# M4KQ register map
File version: 0.1
Registers are 32-bit, read-write, reset 0x0 unless marked. A register's access mark holds for its fields unless they carry their own. Offsets are from the block's base; [hi:lo] are bit positions; {n}, {i} and the like mark numbered series.

## PR — Port R
Base 0x400E0E00
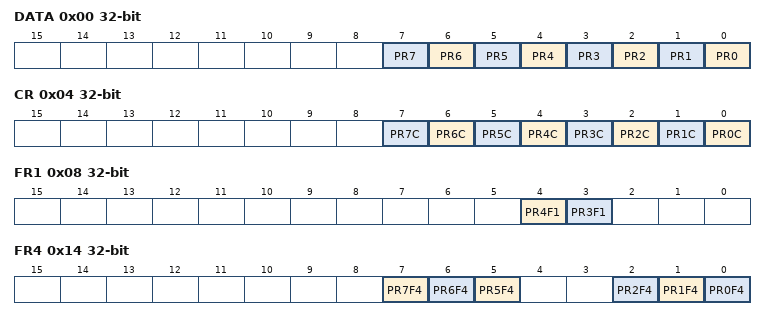
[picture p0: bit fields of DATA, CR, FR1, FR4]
0x00 DATA — Port R Data Register
  [n] PR{n} (n=0..7)
0x04 CR — Port R Output Control Register
  [n] PR{n}C (n=0..7)
0x08 FR1 — Port R Function Register 1
  [4] PR4F1, [3] PR3F1
0x14 FR4 — Port R Function Register 4
  [7] PR7F4, [6] PR6F4, [5] PR5F4, [2] PR2F4, [1] PR1F4, [0] PR0F4
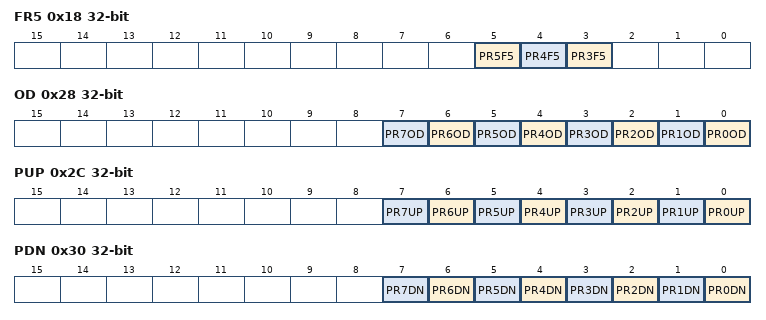
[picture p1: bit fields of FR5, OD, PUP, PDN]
0x18 FR5 — Port R Function Register 5
  [5] PR5F5, [4] PR4F5, [3] PR3F5
0x28 OD — Port R Open Drain Control Register
  [n] PR{n}OD (n=0..7)
0x2C PUP — Port R Pull-up Control Register
  [n] PR{n}UP (n=0..7)
0x30 PDN — Port R Pull-down Control Register
  [n] PR{n}DN (n=0..7)
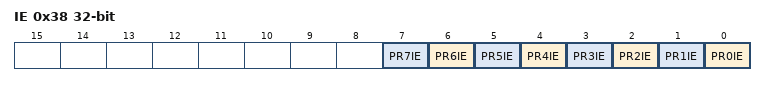
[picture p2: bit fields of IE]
0x38 IE — Port R Input Control Register
  [n] PR{n}IE (n=0..7)

## PT — Port T
Base 0x400E0F00
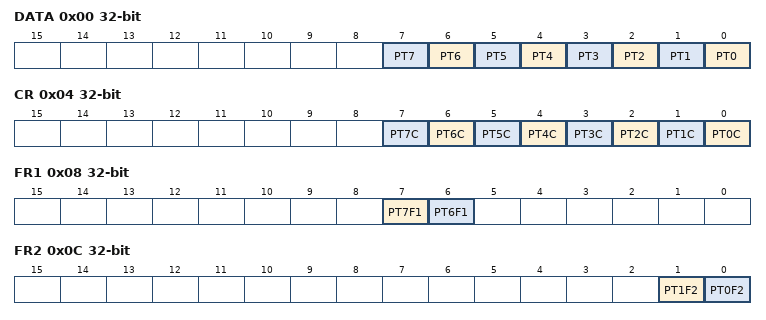
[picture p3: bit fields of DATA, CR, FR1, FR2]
0x00 DATA — Port T Data Register
  [n] PT{n} (n=0..7)
0x04 CR — Port T Output Control Register
  [n] PT{n}C (n=0..7)
0x08 FR1 — Port T Function Register 1
  [7] PT7F1, [6] PT6F1
0x0C FR2 — Port T Function Register 2
  [1] PT1F2, [0] PT0F2
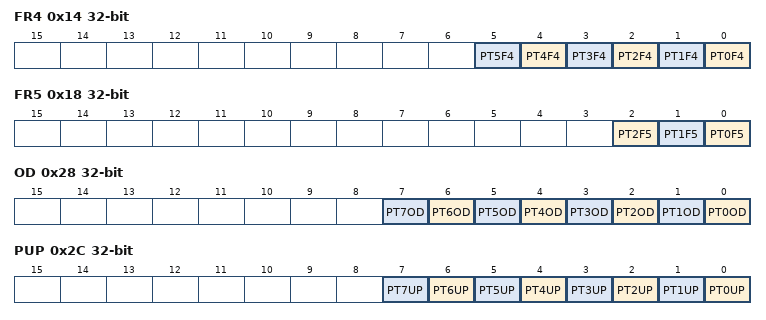
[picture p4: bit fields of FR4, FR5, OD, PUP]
0x14 FR4 — Port T Function Register 4
  [n] PT{n}F4 (n=0..5)
0x18 FR5 — Port T Function Register 5
  [2] PT2F5, [1] PT1F5, [0] PT0F5
0x28 OD — Port T Open Drain Control Register
  [n] PT{n}OD (n=0..7)
0x2C PUP — Port T Pull-up Control Register
  [n] PT{n}UP (n=0..7)
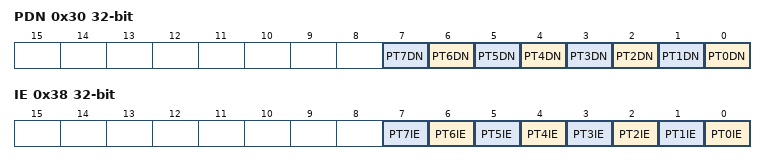
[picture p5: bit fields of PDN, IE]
0x30 PDN — Port T Pull-down Control Register
  [n] PT{n}DN (n=0..7)
0x38 IE — Port T Input Control Register
  [n] PT{n}IE (n=0..7)

## PU — Port U
Base 0x400E1000
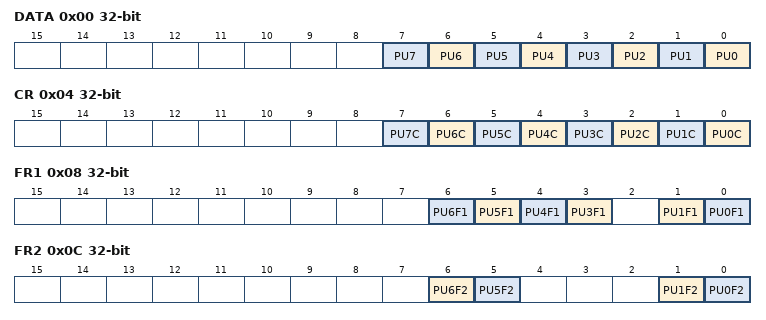
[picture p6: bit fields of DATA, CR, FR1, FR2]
0x00 DATA — Port U Data Register
  [n] PU{n} (n=0..7)
0x04 CR — Port U Output Control Register
  [n] PU{n}C (n=0..7)
0x08 FR1 — Port U Function Register 1
  [n] PU{n}F1 (n=3..6), [1] PU1F1, [0] PU0F1
0x0C FR2 — Port U Function Register 2
  [6] PU6F2, [5] PU5F2, [1] PU1F2, [0] PU0F2
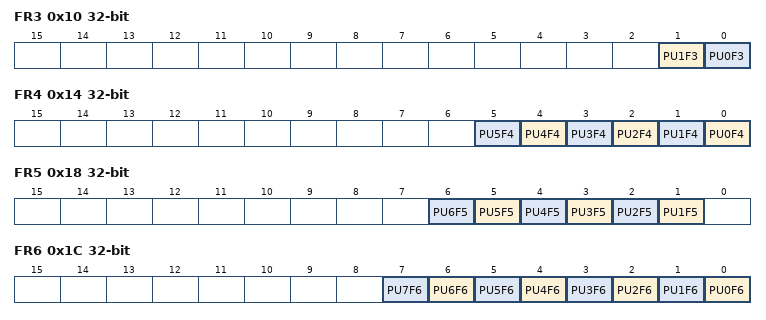
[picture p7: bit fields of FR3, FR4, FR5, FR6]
0x10 FR3 — Port U Function Register 3
  [1] PU1F3, [0] PU0F3
0x14 FR4 — Port U Function Register 4
  [n] PU{n}F4 (n=0..5)
0x18 FR5 — Port U Function Register 5
  [n] PU{n}F5 (n=1..6)
0x1C FR6 — Port U Function Register 6
  [n] PU{n}F6 (n=0..7)
0x20 FR7 — Port U Function Register 7
  [7] PU7F7
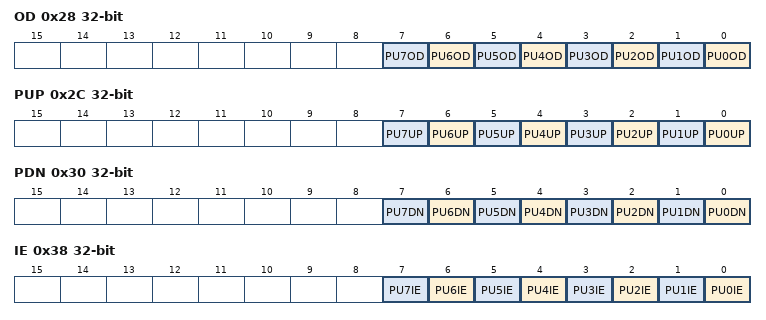
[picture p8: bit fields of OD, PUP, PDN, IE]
0x28 OD — Port U Open Drain Control Register
  [n] PU{n}OD (n=0..7)
0x2C PUP — Port U Pull-up Control Register
  [n] PU{n}UP (n=0..7)
0x30 PDN — Port U Pull-down Control Register
  [n] PU{n}DN (n=0..7)
0x38 IE — Port U Input Control Register
  [n] PU{n}IE (n=0..7)

## PV — Port V
Base 0x400E1100
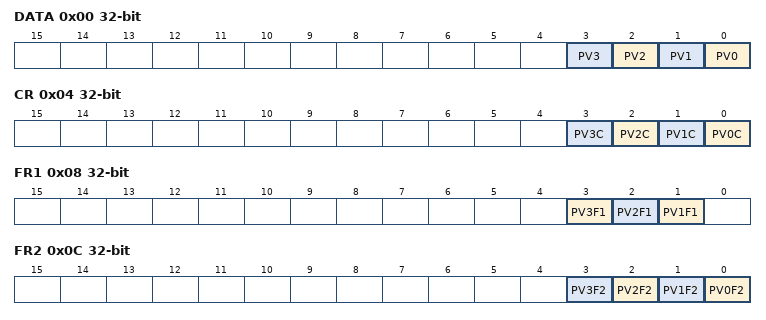
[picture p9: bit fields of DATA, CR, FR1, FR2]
0x00 DATA — Port V Data Register
  [n] PV{n} (n=0..3)
0x04 CR — Port V OutPut Control Register
  [n] PV{n}C (n=0..3)
0x08 FR1 — Port V Function Register 1
  [3] PV3F1, [2] PV2F1, [1] PV1F1
0x0C FR2 — Port V Function Register 2
  [n] PV{n}F2 (n=0..3)
0x14 FR4 — Port V Function Register 4
  [0] PV0F4
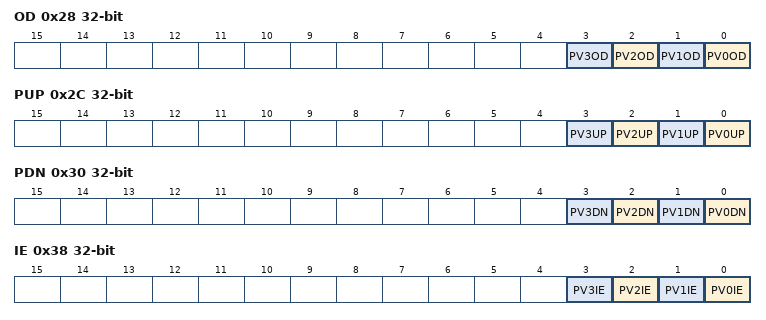
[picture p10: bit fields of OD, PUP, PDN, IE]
0x28 OD — Port V Open Drain Control Register
  [n] PV{n}OD (n=0..3)
0x2C PUP — Port V Pull-up Control Register
  [n] PV{n}UP (n=0..3)
0x30 PDN — Port V Pull-down Control Register
  [n] PV{n}DN (n=0..3)
0x38 IE — Port V InPut Control Register
  [n] PV{n}IE (n=0..3)

## PW — Port W
Base 0x400E1200
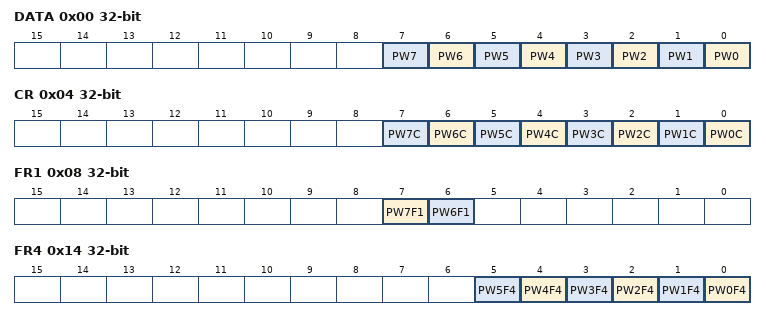
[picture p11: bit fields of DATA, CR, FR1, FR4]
0x00 DATA — Port W Data Register
  [n] PW{n} (n=0..7)
0x04 CR — Port W OutPut Control Register
  [n] PW{n}C (n=0..7)
0x08 FR1 — Port W Function Register 1
  [7] PW7F1, [6] PW6F1
0x14 FR4 — Port W Function Register 4
  [n] PW{n}F4 (n=0..5)
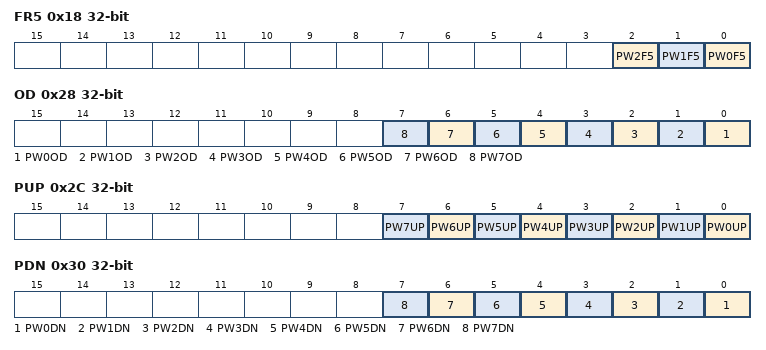
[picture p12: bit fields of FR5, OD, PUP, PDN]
0x18 FR5 — Port W Function Register 5
  [2] PW2F5, [1] PW1F5, [0] PW0F5
0x28 OD — Port W Open Drain Control Register
  [n] PW{n}OD (n=0..7)
0x2C PUP — Port W Pull-up Control Register
  [n] PW{n}UP (n=0..7)
0x30 PDN — Port W Pull-down Control Register
  [n] PW{n}DN (n=0..7)
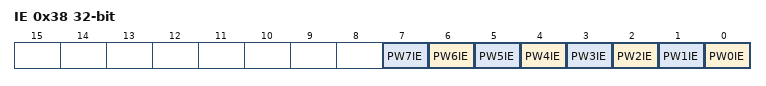
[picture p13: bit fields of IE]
0x38 IE — Port W InPut Control Register
  [n] PW{n}IE (n=0..7)

## TRM — Trimming Circuit (TRM)
Base 0x400E3100
0x00 OSCPRO — Protection Register
  [7:0] PROTECT
0x04 OSCEN — TRM Enable Register
  [0] TRIMEN
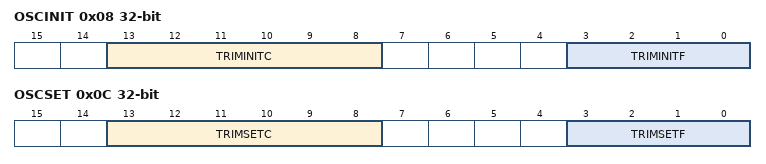
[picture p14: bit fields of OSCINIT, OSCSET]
0x08 OSCINIT ro (reset mask 0xFFFFC0F0) — TRM Initial Trimming Level Monitor Register
  [13:8] TRIMINITC, [3:0] TRIMINITF
0x0C OSCSET — TRM Trimming Level Setting Register
  [13:8] TRIMSETC, [3:0] TRIMSETF
